AUTOSAR XML (schema 00048)
package /ComponentTypes
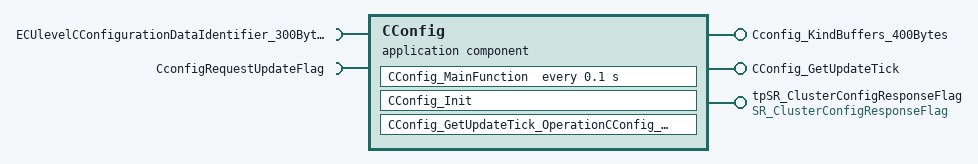
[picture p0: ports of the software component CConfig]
  application sw component type CConfig
    provide port Cconfig_KindBuffers_400Bytes: nonqueued-sender-com-spec{data-element=CconfigKind_400Bytes, init-value=400 x 0}, provided-interface=Cconfig_KindBuffers_400Bytes
    require port ECUlevelCConfigurationDataIdentifier_300Bytes: nonqueued-receiver-com-spec{data-element=Element, filter=data-filter-type=ALWAYS, init-value=300 x 0}, required-interface=ECUlevelCConfigurationDataIdentifier_300Bytes
    provide port CConfig_GetUpdateTick: server-com-spec{operation=OperationCConfig_GetUpdateTick, queue-length=1}, provided-interface=CConfig_GetUpdateTick
    provide port tpSR_ClusterConfigResponseFlag: nonqueued-sender-com-spec=ClusterConfigResponseFlag, provided-interface=SR_ClusterConfigResponseFlag
    require port CconfigRequestUpdateFlag: nonqueued-receiver-com-spec{data-element=CconfigRequestUpdateFlag, filter=data-filter-type=ALWAYS, init-value=0}, required-interface=CconfigRequestUpdateFlag
    behavior CConfig_InternalBehavior
      init event CConfig_InitEvent: start-on-event=CConfig_Init
      timing event TMT_CConfig_MainFunction: start-on-event=CConfig_MainFunction, period=0.1
      operation invoked event OIT_CConfig_GetUpdateTick_OperationCConfig_GetUpdateTick_CConfig_GetUpdateTick_OperationCConfig_GetUpdateTick: start-on-event=CConfig_GetUpdateTick_OperationCConfig_GetUpdateTick, operation=CConfig_GetUpdateTick.OperationCConfig_GetUpdateTick
      runnable CConfig_Init
      runnable CConfig_MainFunction
        data-receive-point-by-arguments:
          access REC_CconfigRequestUpdateFlag_CconfigRequestUpdateFlag: accessed-variable=CconfigRequestUpdateFlag.CconfigRequestUpdateFlag
          access REC_ECUlevelCConfigurationDataIdentifier_300Bytes_Element: accessed-variable=ECUlevelCConfigurationDataIdentifier_300Bytes.Element
        data-send-points:
          access SEND_Cconfig_KindBuffers_400Bytes_CconfigKind_400Bytes: accessed-variable=Cconfig_KindBuffers_400Bytes.CconfigKind_400Bytes
          access SEND_tpSR_ClusterConfigResponseFlag_ClusterConfigResponseFlag: accessed-variable=tpSR_ClusterConfigResponseFlag.ClusterConfigResponseFlag
      runnable CConfig_GetUpdateTick_OperationCConfig_GetUpdateTick
  swc implementation CConfig_Implementation: behavior=CConfig_InternalBehavior
